AUTOSAR XML (schema 4-2-2)
package /Components
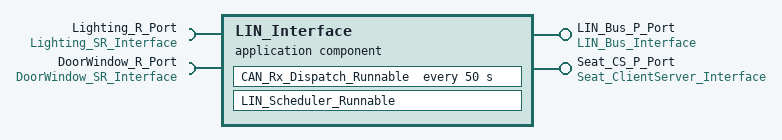
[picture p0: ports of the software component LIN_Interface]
  application sw component type LIN_Interface
    provide port LIN_Bus_P_Port: provided-interface=LIN_Bus_Interface
    provide port Seat_CS_P_Port: provided-interface=Seat_ClientServer_Interface
    require port Lighting_R_Port: required-interface=Lighting_SR_Interface
    require port DoorWindow_R_Port: required-interface=DoorWindow_SR_Interface
    behavior LIN_Interface_InternalBehavior
      data received event LIN_Frame_Received: start-on-event=CAN_Rx_Dispatch_Runnable
      timing event LIN_Schedule_Tick: start-on-event=CAN_Rx_Dispatch_Runnable, period=50
      runnable LIN_Scheduler_Runnable: minimum-start-interval=50, symbol=LIN_Interface_LIN_Scheduler
        data-receive-point-by-arguments:
          access LIN_Receive_VarAccess: accessed-variable=Lighting_R_Port.LIN_Slave_Frame
        data-send-points:
          access LIN_Send_VarAccess: accessed-variable=LIN_Bus_P_Port.LIN_Scheduled_Frame
